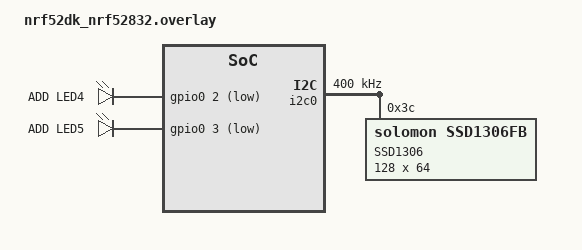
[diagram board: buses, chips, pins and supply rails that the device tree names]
// To get started, press Ctrl+Space to bring up the completion menu and view the available nodes.

// You can also use the buttons in the sidebar to perform actions on nodes.
// Actions currently available include:

// * Enabling / disabling the node
// * Adding the bus to a bus
// * Removing the node
// * Connecting ADC channels

// For more help, browse the DeviceTree documentation at https: //docs.zephyrproject.org/latest/guides/dts/index.html
// You can also visit the nRF DeviceTree extension documentation at https: //nrfconnect.github.io/vscode-nrf-connect/devicetree/nrfdevicetree.html
/*
 * Copyright (c) 2019 Callender-Consulting, LLC
 *
 * SPDX-License-Identifier: Apache-2.0
 */
/ {
    leds {
        compatible = "gpio-leds";
        led4: led_4 {
            gpios = <&gpio0 2 GPIO_ACTIVE_LOW>;
            label = "ADD LED4";
        };
        led5: led_5 {
            gpios = <&gpio0 3 GPIO_ACTIVE_LOW>;
            label = "ADD LED5";
        };

    };
    aliases {
        led4=&led4;//因为是以别名调用这个驱动的所以添加这个别名
        led5=&led5;
    };
};
&i2c0 {
    compatible = "nordic,nrf-twi";
    status = "okay";
    clock-frequency = <I2C_BITRATE_FAST>;

    ssd1306@3c {
        compatible = "solomon,ssd1306fb";
        reg = <0x3c>;
        label = "SSD1306";
        height = <64>;
        width = <128>;
        segment-offset = <0>;
        page-offset = <0>;
        display-offset = <0>;
        multiplex-ratio = <63>;
        prechargep = <0xFF>;
        //s;
        //com-invdir;
        //com-sequential;
    };
};
